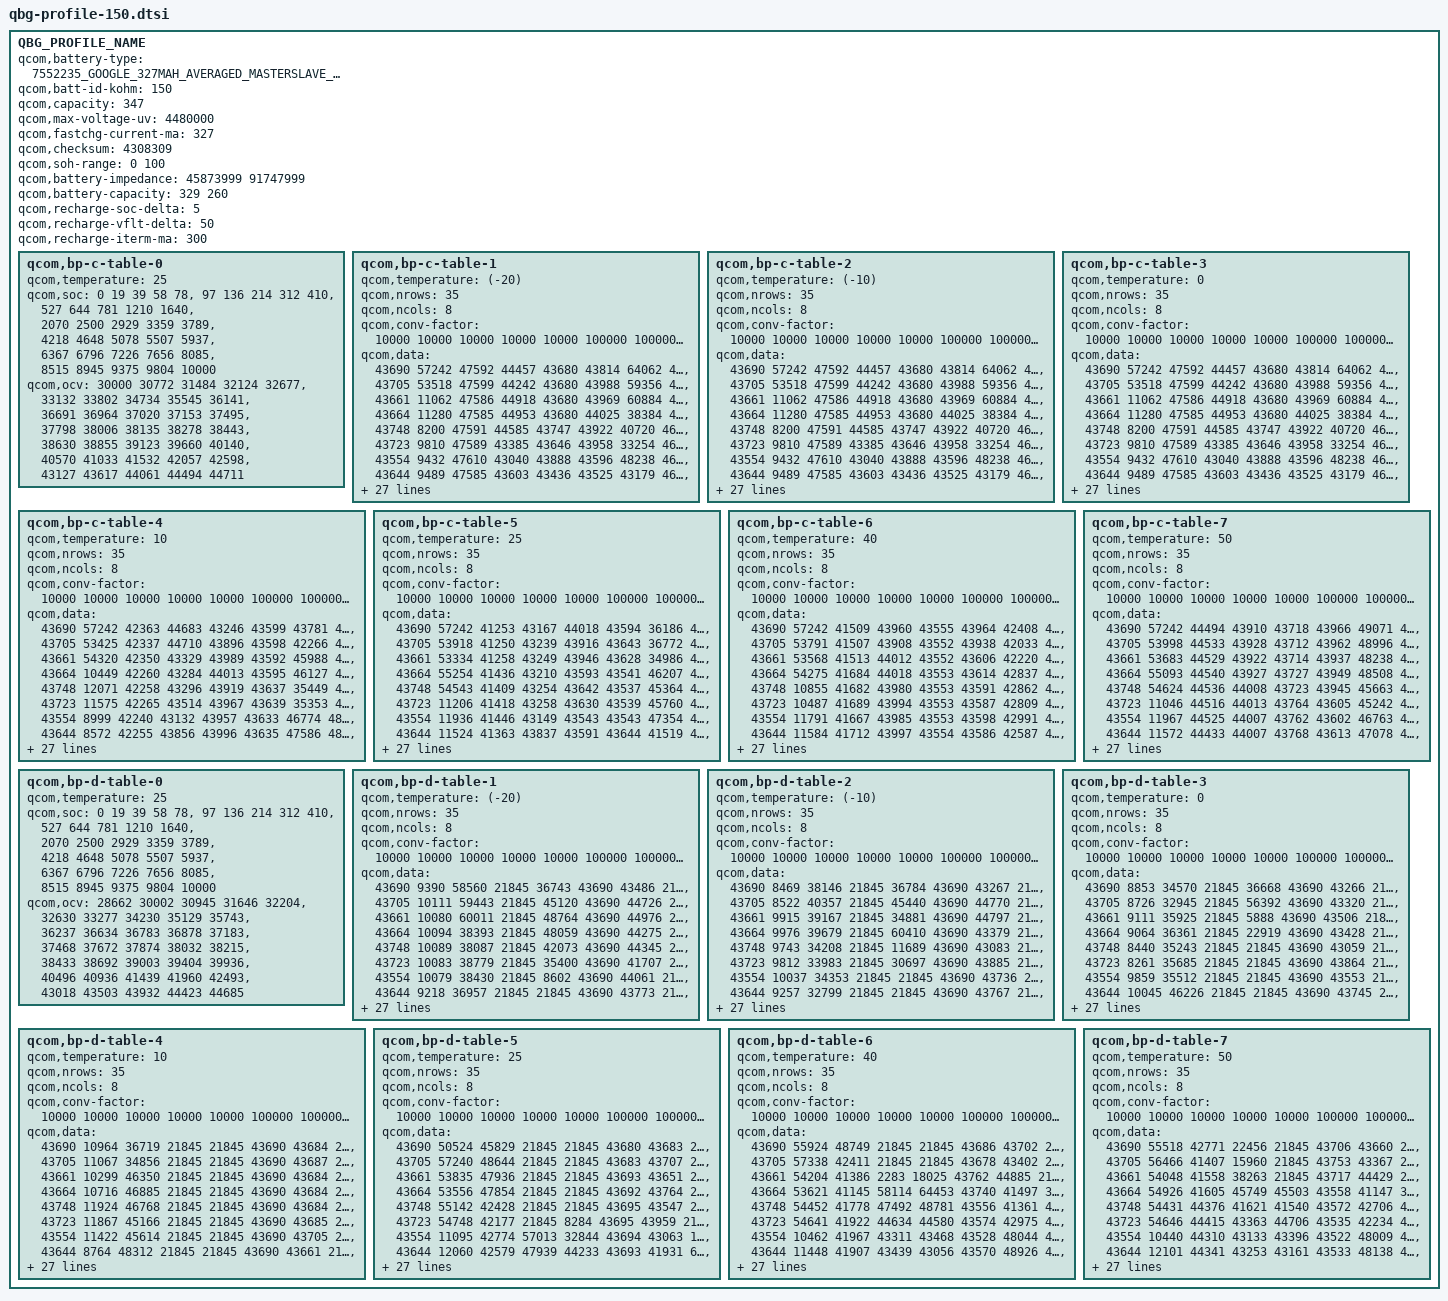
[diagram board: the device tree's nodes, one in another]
/*QBG Profiling Rev. 2.8*/

QBG_PROFILE_NAME {
	qcom,battery-type = "7552235_GOOGLE_327MAH_AVERAGED_MASTERSLAVE_DEC5TH2024";
	qcom,batt-id-kohm = <150>;
	qcom,capacity = <347>;
	qcom,max-voltage-uv = <4480000>;
	qcom,fastchg-current-ma = <327>;
	qcom,checksum = <4308309>; /*@5, 0.005V, 4% */
	qcom,soh-range = <0 100>;
	qcom,battery-impedance = <45873999 91747999>; /*Nominal_Impedance in 10nohm @ SOC 50% 25C* 0:fresh cell, 1: aged cell*/
	qcom,battery-capacity = <329 260>; /*Nominal_Capacity in mAh. 0: fresh cell, 1:aged cell*/
	qcom,recharge-soc-delta =<5>; /*SOC delta (in percent) dropped from EOC SOC to enable recharge*/
	qcom,recharge-vflt-delta =<50>; /*vfloat delta (in mV) dropped from regular vfloat in recharge*/
	qcom,recharge-iterm-ma = <300>; /*termination current (in mA) in recharge*/

	qcom,bp-c-table-0 {
		qcom,temperature = <25>;
		qcom,soc = <    0    19    39    58    78>,
			<   97   136   214   312   410>,
			<  527   644   781  1210  1640>,
			< 2070  2500  2929  3359  3789>,
			< 4218  4648  5078  5507  5937>,
			< 6367  6796  7226  7656  8085>,
			< 8515  8945  9375  9804 10000>;
		qcom,ocv = <30000 30772 31484 32124 32677>,
			<33132 33802 34734 35545 36141>,
			<36691 36964 37020 37153 37495>,
			<37798 38006 38135 38278 38443>,
			<38630 38855 39123 39660 40140>,
			<40570 41033 41532 42057 42598>,
			<43127 43617 44061 44494 44711>;
	};
	qcom,bp-c-table-1 {
		qcom,temperature = <(-20)>;
		qcom,nrows = <35>;
		qcom,ncols = <8>;
		qcom,conv-factor = <10000 10000 10000 10000 10000 100000 100000 10000>;
		qcom,data = <43690 57242 47592 44457 43680 43814 64062 46451>,
			<43705 53518 47599 44242 43680 43988 59356 46342>,
			<43661 11062 47586 44918 43680 43969 60884 46549>,
			<43664 11280 47585 44953 43680 44025 38384 46584>,
			<43748  8200 47591 44585 43747 43922 40720 46477>,
			<43723  9810 47589 43385 43646 43958 33254 46167>,
			<43554  9432 47610 43040 43888 43596 48238 46085>,
			<43644  9489 47585 43603 43436 43525 43179 46233>,
			<43922 15101 47516 43734 43490 43527 43827 46968>,
			<43824 14906 47505 43530 43406 43550 43881 46866>,
			<43173 14956 47515 43632 43402 43542 43847 46927>,
			<43054 14930 47509 43606 43122 43631 43256 46953>,
			<43431 15343 47593 43948 43082 43629 43211 46923>,
			<44560 14386 47451 43973 43345 43551 43857 35504>,
			<44226 14647 48748 41687 43812 43535 45802 36660>,
			<41660 16095 48655 41150 43865 43571 48626 36266>,
			<41838 15938 48842 41369 43248 43571 48468 36126>,
			<41435 16358 48796 41265 43008 43570 48612 33477>,
			<42933 16149 48889 42668 43095 43583 48198 33755>,
			<42087 15609 48691 42711 43496 43576 48579 32804>,
			<47824 15754 48714 42565 43513 43556 45742 33062>,
			<47234 13036 49076 42979 43409 43552 48245 34553>,
			<47484 13160 48939 42793 43393 43561 42013 34745>,
			<48937 12701 48297 42854 43339 43729 41891 33901>,
			<48539 13853 48349 42142 44668 43742 44236 39843>,
			<45685 13555 48225 42185 44893 43719 44571 39404>,
			<45094  2750 48622 42019 44496 43714 43313 40784>,
			<46736  2883 45734 42464 41695 43715 43457 37672>,
			<46914  2428 45670 47694 41579 43743 44705 38863>,
			<46399  3943 45959 42049 42126 43724 43239 59611>,
			<35817  3427 45905 42482 47336 43715 43190 58334>,
			<34907   794 45290 42341 45774 43712 43853 63589>,
			<36405   450 45266 42262 36862 43718 43807 52870>,
			<36070  1977 45070 42978 33964 43725 44030 50412>,
			<36282  1868 45162 41706 33945 43763 43594 50844>;
	};
	qcom,bp-c-table-2 {
		qcom,temperature = <(-10)>;
		qcom,nrows = <35>;
		qcom,ncols = <8>;
		qcom,conv-factor = <10000 10000 10000 10000 10000 100000 100000 10000>;
		qcom,data = <43690 57242 47592 44457 43680 43814 64062 46451>,
			<43705 53518 47599 44242 43680 43988 59356 46342>,
			<43661 11062 47586 44918 43680 43969 60884 46549>,
			<43664 11280 47585 44953 43680 44025 38384 46584>,
			<43748  8200 47591 44585 43747 43922 40720 46477>,
			<43723  9810 47589 43385 43646 43958 33254 46167>,
			<43554  9432 47610 43040 43888 43596 48238 46085>,
			<43644  9489 47585 43603 43436 43525 43179 46233>,
			<43922 15101 47516 43734 43490 43527 43827 46968>,
			<43824 14906 47505 43530 43406 43550 43881 46866>,
			<43173 14956 47515 43632 43402 43542 43847 46927>,
			<43054 14930 47509 43606 43122 43631 43256 46953>,
			<43431 15343 47593 43948 43082 43629 43211 46923>,
			<44560 14386 47451 43973 43345 43551 43857 35504>,
			<44226 14647 48748 41687 43812 43535 45802 36660>,
			<41660 16095 48655 41150 43865 43571 48626 36266>,
			<41838 15938 48842 41369 43248 43571 48468 36126>,
			<41435 16358 48796 41265 43008 43570 48612 33477>,
			<42933 16149 48889 42668 43095 43583 48198 33755>,
			<42087 15609 48691 42711 43496 43576 48579 32804>,
			<47824 15754 48714 42565 43513 43556 45742 33062>,
			<47234 13036 49076 42979 43409 43552 48245 34553>,
			<47484 13160 48939 42793 43393 43561 42013 34745>,
			<48937 12701 48297 42854 43339 43729 41891 33901>,
			<48539 13853 48349 42142 44668 43742 44236 39843>,
			<45685 13555 48225 42185 44893 43719 44571 39404>,
			<45094  2750 48622 42019 44496 43714 43313 40784>,
			<46736  2883 45734 42464 41695 43715 43457 37672>,
			<46914  2428 45670 47694 41579 43743 44705 38863>,
			<46399  3943 45959 42049 42126 43724 43239 59611>,
			<35817  3427 45905 42482 47336 43715 43190 58334>,
			<34907   794 45290 42341 45774 43712 43853 63589>,
			<36405   450 45266 42262 36862 43718 43807 52870>,
			<36070  1977 45070 42978 33964 43725 44030 50412>,
			<36282  1868 45162 41706 33945 43763 43594 50844>;
	};
	qcom,bp-c-table-3 {
		qcom,temperature = <0>;
		qcom,nrows = <35>;
		qcom,ncols = <8>;
		qcom,conv-factor = <10000 10000 10000 10000 10000 100000 100000 10000>;
		qcom,data = <43690 57242 47592 44457 43680 43814 64062 46451>,
			<43705 53518 47599 44242 43680 43988 59356 46342>,
			<43661 11062 47586 44918 43680 43969 60884 46549>,
			<43664 11280 47585 44953 43680 44025 38384 46584>,
			<43748  8200 47591 44585 43747 43922 40720 46477>,
			<43723  9810 47589 43385 43646 43958 33254 46167>,
			<43554  9432 47610 43040 43888 43596 48238 46085>,
			<43644  9489 47585 43603 43436 43525 43179 46233>,
			<43922 15101 47516 43734 43490 43527 43827 46968>,
			<43824 14906 47505 43530 43406 43550 43881 46866>,
			<43173 14956 47515 43632 43402 43542 43847 46927>,
			<43054 14930 47509 43606 43122 43631 43256 46953>,
			<43431 15343 47593 43948 43082 43629 43211 46923>,
			<44560 14386 47451 43973 43345 43551 43857 35504>,
			<44226 14647 48748 41687 43812 43535 45802 36660>,
			<41660 16095 48655 41150 43865 43571 48626 36266>,
			<41838 15938 48842 41369 43248 43571 48468 36126>,
			<41435 16358 48796 41265 43008 43570 48612 33477>,
			<42933 16149 48889 42668 43095 43583 48198 33755>,
			<42087 15609 48691 42711 43496 43576 48579 32804>,
			<47824 15754 48714 42565 43513 43556 45742 33062>,
			<47234 13036 49076 42979 43409 43552 48245 34553>,
			<47484 13160 48939 42793 43393 43561 42013 34745>,
			<48937 12701 48297 42854 43339 43729 41891 33901>,
			<48539 13853 48349 42142 44668 43742 44236 39843>,
			<45685 13555 48225 42185 44893 43719 44571 39404>,
			<45094  2750 48622 42019 44496 43714 43313 40784>,
			<46736  2883 45734 42464 41695 43715 43457 37672>,
			<46914  2428 45670 47694 41579 43743 44705 38863>,
			<46399  3943 45959 42049 42126 43724 43239 59611>,
			<35817  3427 45905 42482 47336 43715 43190 58334>,
			<34907   794 45290 42341 45774 43712 43853 63589>,
			<36405   450 45266 42262 36862 43718 43807 52870>,
			<36070  1977 45070 42978 33964 43725 44030 50412>,
			<36282  1868 45162 41706 33945 43763 43594 50844>;
	};
	qcom,bp-c-table-4 {
		qcom,temperature = <10>;
		qcom,nrows = <35>;
		qcom,ncols = <8>;
		qcom,conv-factor = <10000 10000 10000 10000 10000 100000 100000 10000>;
		qcom,data = <43690 57242 42363 44683 43246 43599 43781 46028>,
			<43705 53425 42337 44710 43896 43598 42266 45960>,
			<43661 54320 42350 43329 43989 43592 45988 45687>,
			<43664 10449 42260 43284 44013 43595 46127 45618>,
			<43748 12071 42258 43296 43919 43637 35449 45820>,
			<43723 11575 42265 43514 43967 43639 35353 45759>,
			<43554  8999 42240 43132 43957 43633 46774 48436>,
			<43644  8572 42255 43856 43996 43635 47586 48195>,
			<43922  9396 42242 43609 43247 43639 43232 48344>,
			<43824  9502 42279 43616 43213 43589 43857 48364>,
			<43173 15062 42454 43717 43067 43938 43835 48962>,
			<43054 14848 42435 43618 43219 43615 43892 48983>,
			<43431 14973 42433 43599 43158 43615 43233 49011>,
			<44560 15125 42296 43384 43589 43642 49101 48586>,
			<44226 14765 42391 44814 43952 43525 45341 45635>,
			<41660 16047 42072 44227 44015 43532 46613 46068>,
			<41838 15900 41989 44154 43971 43529 46028 45861>,
			<41435 16267 42032 44100 43833 43528 48502 45850>,
			<42933 16177 42192 44452 43886 43531 49097 45892>,
			<42087 15489 42193 44541 43867 43572 48356 45260>,
			<47824 15432 42028 44289 43192 43569 45863 45172>,
			<47234 15720 42022 41627 43146 43570 36754 45527>,
			<47484 13307 42036 41710 43845 43582 46484 45520>,
			<48937 12694 42089 41701 43888 43559 42422 45371>,
			<48539 13937 42074 41593 43167 43566 40975 46622>,
			<45685 13356 42386 41972 43034 43734 41608 46217>,
			<45094  2788 42298 41805 43495 43742 44260 46442>,
			<46736  2202 42352 40985 43383 43716 44909 35585>,
			<46914  3717 47773 41356 44641 43713 44670 35090>,
			<46399  3307 47665 41456 44259 43713 43380 36068>,
			<35817   742 48059 41263 41506 43719 43419 33637>,
			<34907   158 48073 41261 42735 43739 43039 33887>,
			<36405   324 47909 41382 48752 43741 43142 37487>,
			<36070  1846 47895 41628 48638 43739 43893 36895>,
			<36282  1229 48122 44669 45780 43715 43947 37711>;
	};
	qcom,bp-c-table-5 {
		qcom,temperature = <25>;
		qcom,nrows = <35>;
		qcom,ncols = <8>;
		qcom,conv-factor = <10000 10000 10000 10000 10000 100000 100000 10000>;
		qcom,data = <43690 57242 41253 43167 44018 43594 36186 47882>,
			<43705 53918 41250 43239 43916 43643 36772 48070>,
			<43661 53334 41258 43249 43946 43628 34986 48019>,
			<43664 55254 41436 43210 43593 43541 46207 48045>,
			<43748 54543 41409 43254 43642 43537 45364 47740>,
			<43723 11206 41418 43258 43630 43539 45760 47628>,
			<43554 11936 41446 43149 43543 43543 47354 47845>,
			<43644 11524 41363 43837 43591 43644 41519 42343>,
			<43922  8307 41351 43611 43819 43944 43108 42450>,
			<43824 10119 41381 43634 43837 43605 43062 42465>,
			<43173  9721 41384 43958 43935 43600 44652 42406>,
			<43054 15054 41049 43615 44027 43639 43474 42055>,
			<43431 14902 41029 43598 43968 43646 43421 42058>,
			<44560 15243 41079 43099 43610 43550 47977 47860>,
			<44226 14557 40962 43370 43907 43533 47279 48051>,
			<41660 14604 41169 44675 43922 43531 48681 48119>,
			<41838 16092 41213 44739 43929 43573 48211 48069>,
			<41435 15965 41111 44764 44011 43530 48613 48068>,
			<42933 16172 41103 44784 43999 43530 47776 48079>,
			<42087 15489 41142 44673 43900 43572 41047 47919>,
			<47824 15436 41123 44696 43180 43569 41226 47875>,
			<47234 15725 41133 44744 43170 43568 42486 47990>,
			<47484 12921 41820 44561 43889 43530 46370 47937>,
			<48937 12358 41819 44578 44027 43575 47384 48027>,
			<48539 13926 41819 44758 44026 43571 41319 48011>,
			<45685 13520 41810 44671 43816 43556 41949 47983>,
			<45094  2787 41147 45009 43898 43563 44405 47180>,
			<46736  2198 41116 44884 43167 43731 44093 48809>,
			<46914  3811 41166 44224 43030 43743 44857 49130>,
			<46399  3276 41008 44032 43308 43742 44546 48143>,
			<35817   733 41074 44106 44555 43740 44683 45770>,
			<34907   203 41392 44102 44035 43732 43475 45476>,
			<36405  1719 41462 44234 41967 43558 43504 46974>,
			<36070  1892 41258 44929 41424 43564 43072 46458>,
			<36282  1037 41031 43289 42842 43742 44017 35391>;
	};
	qcom,bp-c-table-6 {
		qcom,temperature = <40>;
		qcom,nrows = <35>;
		qcom,ncols = <8>;
		qcom,conv-factor = <10000 10000 10000 10000 10000 100000 100000 10000>;
		qcom,data = <43690 57242 41509 43960 43555 43964 42408 40983>,
			<43705 53791 41507 43908 43552 43938 42033 41076>,
			<43661 53568 41513 44012 43552 43606 42220 41042>,
			<43664 54275 41684 44018 43553 43614 42837 41382>,
			<43748 10855 41682 43980 43553 43591 42862 41393>,
			<43723 10487 41689 43994 43553 43587 42809 41356>,
			<43554 11791 41667 43985 43553 43598 42991 41368>,
			<43644 11584 41712 43997 43554 43586 42587 41346>,
			<43922  8265 41703 44028 43567 43600 42739 41025>,
			<43824 10164 41710 44024 43559 43607 41461 41034>,
			<43173  9626 41622 43952 43527 43965 41643 40977>,
			<43054 15074 41630 43916 43717 43939 42478 41173>,
			<43431 15056 41601 43927 43716 43604 48063 41016>,
			<44560 14937 41651 43897 43605 43623 41130 41321>,
			<44226 14485 41642 43159 43910 43538 41152 42745>,
			<41660 14838 44354 43042 43957 43544 47917 42718>,
			<41838 16026 44411 43059 43939 43524 48679 42690>,
			<41435 15993 44309 43067 43951 43524 47775 42723>,
			<42933 16325 44294 43068 43917 43544 42881 42696>,
			<42087 15497 44342 43188 43848 43551 44927 42535>,
			<47824 15429 44347 43184 43187 43524 44179 42602>,
			<47234 15735 44322 43256 43196 43522 41587 42566>,
			<47484 12886 44329 43036 43899 43522 48088 42920>,
			<48937 12709 44503 43060 43910 43523 42935 42733>,
			<48539 13943 44499 43206 44009 43522 44351 42654>,
			<45685 13375 44496 43229 43994 43531 44839 42695>,
			<45094  2754 44501 43017 43827 43568 44658 42610>,
			<46736  2292 44332 43402 43897 43558 44555 42765>,
			<46914  3783 44344 43280 43149 43560 44752 42008>,
			<46399  3104 44294 44718 43018 43563 44681 42297>,
			<35817   572 44386 44768 43415 43564 44713 47674>,
			<34907   223 44355 44554 44728 43580 44793 47936>,
			<36405  1668 41636 43289 44771 43528 44671 48023>,
			<36070  1870 41631 43410 44035 43573 43484 47558>,
			<36282  1130 44540 43871 42645 43568 43973 48192>;
	};
	qcom,bp-c-table-7 {
		qcom,temperature = <50>;
		qcom,nrows = <35>;
		qcom,ncols = <8>;
		qcom,conv-factor = <10000 10000 10000 10000 10000 100000 100000 10000>;
		qcom,data = <43690 57242 44494 43910 43718 43966 49071 41880>,
			<43705 53998 44533 43928 43712 43962 48996 41965>,
			<43661 53683 44529 43922 43714 43937 48238 41971>,
			<43664 55093 44540 43927 43727 43949 48508 41923>,
			<43748 54624 44536 44008 43723 43945 45663 41951>,
			<43723 11046 44516 44013 43764 43605 45242 41941>,
			<43554 11967 44525 44007 43762 43602 46763 41766>,
			<43644 11572 44433 44007 43768 43613 47078 41762>,
			<43922  8296 44443 44002 43774 43601 45499 41949>,
			<43824  9812 44417 43606 43553 43966 41088 41976>,
			<43173  9301 44431 43588 43579 43905 41244 41873>,
			<43054 15030 44469 43643 43716 43911 41335 41561>,
			<43431 15073 44464 43584 43727 43915 47665 41898>,
			<44560 14946 44452 43982 43606 43585 41692 41090>,
			<44226 14525 44116 43827 43958 43633 41474 41174>,
			<41660 14725 44122 43794 43915 43647 42723 41017>,
			<41838 16035 44105 43792 43941 43642 42876 41171>,
			<41435 15894 44156 43878 43597 43623 42147 41204>,
			<42933 16335 44131 43889 43605 43642 42703 41000>,
			<42087 15499 44055 43998 43804 43639 44954 40983>,
			<47824 15453 44060 44004 43175 43643 44636 41028>,
			<47234 15685 44037 43815 43857 43629 44392 41403>,
			<47484 13237 44032 43855 43776 43629 42424 41405>,
			<48937 12673 44044 43850 43946 43629 42504 41152>,
			<48539 13918 44046 43837 43917 43619 44271 41190>,
			<45685 13316 44041 43836 43983 43624 44687 40994>,
			<45094  2601 44047 43891 43999 43544 44794 41053>,
			<46736  2262 44032 43136 43833 43535 44778 41428>,
			<46914  3621 44058 43042 43840 43570 43391 42732>,
			<46399  3087 44051 43429 43156 43576 44713 42884>,
			<35817   514 44141 43507 43057 43576 44791 42817>,
			<34907    47 44146 43470 43481 43568 44705 42085>,
			<36405  1692 44100 43032 43421 43525 45012 42877>,
			<36070  1856 44116 43070 44627 43550 44708 42279>,
			<36282  1127 44241 43197 41546 43539 43897 47261>;
	};
	qcom,bp-d-table-0 {
		qcom,temperature = <25>;
		qcom,soc = <    0    19    39    58    78>,
			<   97   136   214   312   410>,
			<  527   644   781  1210  1640>,
			< 2070  2500  2929  3359  3789>,
			< 4218  4648  5078  5507  5937>,
			< 6367  6796  7226  7656  8085>,
			< 8515  8945  9375  9804 10000>;
		qcom,ocv = <28662 30002 30945 31646 32204>,
			<32630 33277 34230 35129 35743>,
			<36237 36634 36783 36878 37183>,
			<37468 37672 37874 38032 38215>,
			<38433 38692 39003 39404 39936>,
			<40496 40936 41439 41960 42493>,
			<43018 43503 43932 44423 44685>;
	};
	qcom,bp-d-table-1 {
		qcom,temperature = <(-20)>;
		qcom,nrows = <35>;
		qcom,ncols = <8>;
		qcom,conv-factor = <10000 10000 10000 10000 10000 100000 100000 10000>;
		qcom,data = <43690  9390 58560 21845 36743 43690 43486 21845>,
			<43705 10111 59443 21845 45120 43690 44726 21845>,
			<43661 10080 60011 21845 48764 43690 44976 21845>,
			<43664 10094 38393 21845 48059 43690 44275 21845>,
			<43748 10089 38087 21845 42073 43690 44345 21845>,
			<43723 10083 38779 21845 35400 43690 41707 21845>,
			<43554 10079 38430 21845  8602 43690 44061 21845>,
			<43644  9218 36957 21845 21845 43690 43773 21845>,
			<43922  9303 36887 21845  6087 43690 43731 21845>,
			<43824  9607 37022 21845 55622 43690 43579 21845>,
			<43173  9669 40149 21845 59179 43690 43523 21845>,
			<43054  9495 40861 21845 39998 43690 43585 21845>,
			<43431 15034 39288 21845 33416 43690 44009 21845>,
			<44560 14949 39456 23215 36810 43691 43898 21845>,
			<44226 15317 34023 12936 46136 43691 43256 21845>,
			<41660 14516 33147 50890 45724 43688 43111 21845>,
			<41838 14362 33557 58835 47229 43688 43397 24414>,
			<41435 14829 33477 38142 42486 43689 43322 31638>,
			<42933 14666 36132 39778 42599 43689 43389  8129>,
			<42087 15906 36086 33726 41396 43694 44681  2986>,
			<47824 16278 36753 34893 41854 43695 44760 15328>,
			<47234 15535 36581 46120 41693 43692 44983 11984>,
			<47484 15446 35111 45370 44438 43693 44140 53450>,
			<48937 13028 35216 45238 44060 43682 41776 56982>,
			<48539 13138 34901 46003 44350 43682 41471 56110>,
			<45685 12663 34878 45767 41664 43683 42932 55997>,
			<45094 13486 35014 45615 41739 43680 42118 55918>,
			<46736  2749 35064 45619 41030 43681 42934 56081>,
			<46914  2206 35047 45775 41254 43703 42709 55296>,
			<46399  3626 35016 45717 41342 43669 42123 55621>,
			<35817  3126 35669 45659 42702 43670 42603 56950>,
			<34907   520 35054 45974 42698 43677 41155 57262>,
			<36405    14 35652 45930 41192 43652 41498 55806>,
			<36070  1943 35752 45266 44249 43659 44348 55950>,
			<36282  1050 35539 45114 44826 43696 44482 50648>;
	};
	qcom,bp-d-table-2 {
		qcom,temperature = <(-10)>;
		qcom,nrows = <35>;
		qcom,ncols = <8>;
		qcom,conv-factor = <10000 10000 10000 10000 10000 100000 100000 10000>;
		qcom,data = <43690  8469 38146 21845 36784 43690 43267 21845>,
			<43705  8522 40357 21845 45440 43690 44770 21845>,
			<43661  9915 39167 21845 34881 43690 44797 21845>,
			<43664  9976 39679 21845 60410 43690 43379 21845>,
			<43748  9743 34208 21845 11689 43690 43083 21845>,
			<43723  9812 33983 21845 30697 43690 43885 21845>,
			<43554 10037 34353 21845 21845 43690 43736 21845>,
			<43644  9257 32799 21845 21845 43690 43767 21845>,
			<43922  9302 33758 21845 49551 43690 43568 21845>,
			<43824  9715 33423 21845 40905 43690 43585 21845>,
			<43173  9500 36045 21845 46138 43690 44019 21845>,
			<43054 15021 36822 30323 47402 43690 43844 21845>,
			<43431 15093 35202 56473 42956 43691 43106 21845>,
			<44560 15234 35468 40682 41079 43688 43340  6002>,
			<44226 15124 46856 34935 41908 43689 44581 10033>,
			<41660 14564 46796 45950 44447 43695 44948 55427>,
			<41838 14455 45508 48652 44893 43693 44814 51373>,
			<41435 14789 45536 47935 44959 43680 44172 62284>,
			<42933 16039 45510 42301 44644 43687 44078 65076>,
			<42087 15969 45509 42024 44745 43707 44367 64393>,
			<47824 16250 45532 42870 44673 43650 42512 58625>,
			<47234 15799 45353 42895 44584 43745 47741 58855>,
			<47484 12833 45518 42531 44986 43731 48091 58830>,
			<48937 13141 45507 42517 44803 43735 41989 58861>,
			<48539 12561 45331 42975 44267 43560 41998 58751>,
			<45685 14088 45370 42118 44464 43563 42949 64037>,
			<45094 13578 45559 42392 44350 43734 42514 64469>,
			<46736  2845 45460 47828 44381 43743 42506 63595>,
			<46914  2416 45444 47925 41686 43713 42720 63836>,
			<46399  3904 45459 47317 41566 43721 41457 65419>,
			<35817  3440 45498 47592 41952 43766 41100 64666>,
			<34907   819 45152 47487 41889 43775 41572 64624>,
			<36405   490 45144 47444 44543 43745 41508 64654>,
			<36070  2014 45349 47378 44768 43754 41577 65202>,
			<36282  1055 45395 47602 43468 43664 41908 63918>;
	};
	qcom,bp-d-table-3 {
		qcom,temperature = <0>;
		qcom,nrows = <35>;
		qcom,ncols = <8>;
		qcom,conv-factor = <10000 10000 10000 10000 10000 100000 100000 10000>;
		qcom,data = <43690  8853 34570 21845 36668 43690 43266 21845>,
			<43705  8726 32945 21845 56392 43690 43320 21845>,
			<43661  9111 35925 21845  5888 43690 43506 21845>,
			<43664  9064 36361 21845 22919 43690 43428 21845>,
			<43748  8440 35243 21845 21845 43690 43059 21845>,
			<43723  8261 35685 21845 21845 43690 43864 21845>,
			<43554  9859 35512 21845 21845 43690 43553 21845>,
			<43644 10045 46226 21845 21845 43690 43745 21845>,
			<43922  9262 46717 21845 64215 43690 43532 21845>,
			<43824  9639 45408 21845 46291 43690 43908 21845>,
			<43173  9694 45096 27370 42890 43690 43136 21845>,
			<43054  9492 45858 63688 44355 43691 43428 23464>,
			<43431 15008 45684 36430 44214 43688 43323  2301>,
			<44560 14914 48249 42565 43323 43695 44064 62103>,
			<44226 15134 48924 42427 43501 43682 41022 64199>,
			<41660 14559 49100 42558 43460 43706 42748 60697>,
			<41838 14721 49098 41089 43441 43772 47160 59579>,
			<41435 14620 48955 41898 43131 43742 47875 38702>,
			<42933 16123 48941 41573 43104 43728 47661 37076>,
			<42087 16284 49109 41572 43101 43562 47196 37810>,
			<47824 15597 48943 41596 43319 43561 47330 37586>,
			<47234 15858 49009 41577 44723 43566 42942 40256>,
			<47484 12810 48968 41917 44758 43554 41461 40312>,
			<48937 12426 48915 41836 44644 43554 41354 37543>,
			<48539 12659 48950 41017 45054 43561 41004 37379>,
			<45685 14176 48902 41267 44875 43734 41137 37642>,
			<45094 13643 48922 42592 44262 43742 41145 36970>,
			<46736  2901 48955 42855 44054 43715 41748 37241>,
			<46914  3775 48932 42023 44427 43722 41534 38527>,
			<46399  3215 49141 42473 44436 43761 41623 38783>,
			<35817   689 49100 42313 44437 43773 41632 37892>,
			<34907   841 49041 47865 44109 43769 41661 38286>,
			<36405   464 49049 47803 44806 43751 41685 38110>,
			<36070  1836 49148 42429 43324 43753 41876 38454>,
			<36282  1050 49118 42203 43112 43668 41951 37216>;
	};
	qcom,bp-d-table-4 {
		qcom,temperature = <10>;
		qcom,nrows = <35>;
		qcom,ncols = <8>;
		qcom,conv-factor = <10000 10000 10000 10000 10000 100000 100000 10000>;
		qcom,data = <43690 10964 36719 21845 21845 43690 43684 21845>,
			<43705 11067 34856 21845 21845 43690 43687 21845>,
			<43661 10299 46350 21845 21845 43690 43684 21845>,
			<43664 10716 46885 21845 21845 43690 43684 21845>,
			<43748 11924 46768 21845 21845 43690 43684 21845>,
			<43723 11867 45166 21845 21845 43690 43685 21845>,
			<43554 11422 45614 21845 21845 43690 43705 21845>,
			<43644  8764 48312 21845 21845 43690 43661 21845>,
			<43922  8600 48888 21845  3391 43690 43557 21845>,
			<43824 10216 47563 21845 46422 43690 43827 21845>,
			<43173  9324 47158 53024 41152 43691 43513 21845>,
			<43054  9713 47253 36490 45050 43691 44968 12821>,
			<43431  9473 47908 42848 43509 43694 44240 62796>,
			<44560 14995 47916 44223 43853 43650 41694 40843>,
			<44226 15136 48040 44139 43221 43761 42828 39025>,
			<41660 14374 47631 44154 43428 43731 42250 34000>,
			<41838 14722 47635 44071 43429 43560 42175 32920>,
			<41435 14598 47636 44235 43009 43554 42872 36273>,
			<42933 16067 47728 44077 43056 43559 47194 36630>,
			<42087 16363 47627 44231 43095 43556 47653 36768>,
			<47824 15496 47647 44256 43501 43556 41312 36602>,
			<47234 15749 47726 44241 43509 43579 41110 35142>,
			<47484 13022 47717 44121 43479 43557 41108 36514>,
			<48937 13145 47722 44331 43292 43552 41193 36551>,
			<48539 12651 47623 41628 44721 43565 40976 36757>,
			<45685 14154 47630 41953 44554 43567 42496 35858>,
			<45094  2744 47627 41089 44929 43733 42999 33414>,
			<46736  2213 47636 41165 44855 43739 41879 33365>,
			<46914  3766 47836 41081 44817 43718 44355 33656>,
			<46399  3201 47830 41456 44853 43725 44347 32821>,
			<35817   647 47811 41321 45022 43721 44384 33252>,
			<34907   171 47817 41286 44959 43722 41606 33144>,
			<36405   308 47817 41240 44590 43760 41597 33031>,
			<36070  1851 47822 41388 43514 43768 41831 32866>,
			<36282  1036 47823 41066 43108 43748 41192 32956>;
	};
	qcom,bp-d-table-5 {
		qcom,temperature = <25>;
		qcom,nrows = <35>;
		qcom,ncols = <8>;
		qcom,conv-factor = <10000 10000 10000 10000 10000 100000 100000 10000>;
		qcom,data = <43690 50524 45829 21845 21845 43680 43683 21845>,
			<43705 57240 48644 21845 21845 43683 43707 21845>,
			<43661 53835 47936 21845 21845 43693 43651 21845>,
			<43664 53556 47854 21845 21845 43692 43764 21845>,
			<43748 55142 42428 21845 21845 43695 43547 21845>,
			<43723 54748 42177 21845  8284 43695 43959 21845>,
			<43554 11095 42774 57013 32844 43694 43063 19130>,
			<43644 12060 42579 47939 44233 43693 41931 65524>,
			<43922  9107 42558 44032 43490 43675 48748 39424>,
			<43824  8501 42548 45054 43075 43771 45902 35920>,
			<43173 10023 42529 44588 43183 43723 47902 35541>,
			<43054  9648 42718 44692 43194 43741 41056 46977>,
			<43431  9477 42738 44673 43873 43741 41183 45499>,
			<44560 15012 42626 43451 43944 43555 42552 49010>,
			<44226 15253 42686 43513 43821 43557 41274 48952>,
			<41660 14582 41237 43271 43153 43581 41176 48950>,
			<41838 14722 41256 43287 43042 43531 41393 49072>,
			<41435 14680 41250 43344 43038 43545 47784 49066>,
			<42933 15930 41465 43276 43086 43521 41382 48832>,
			<42087 16365 41455 43268 43028 43524 41786 47444>,
			<47824 15499 41369 43372 43220 43526 41887 47411>,
			<47234 15758 41398 43331 43240 43522 41728 47611>,
			<47484 13041 41383 44718 43159 43528 41122 47587>,
			<48937 13126 41391 44770 43230 43531 42671 47370>,
			<48539 13994 41047 44614 43409 43523 42316 49086>,
			<45685 13466 41037 44930 44691 43529 42384 48362>,
			<45094 13634 41025 44660 44780 43556 41640 48314>,
			<46736  2933 41040 44988 43344 43577 44458 48279>,
			<46914  2370 41391 45031 43326 43577 44081 48275>,
			<46399  3927 41403 44810 43455 43579 44434 48353>,
			<35817   672 41369 44916 43032 43578 41479 48341>,
			<34907   837 41362 44819 43033 43558 41965 48142>,
			<36405   310 41451 45004 43012 43552 41949 48191>,
			<36070  1837 41471 44632 43064 43565 41934 48334>,
			<36282  1063 41462 44655 43048 43564 41546 48382>;
	};
	qcom,bp-d-table-6 {
		qcom,temperature = <40>;
		qcom,nrows = <35>;
		qcom,ncols = <8>;
		qcom,conv-factor = <10000 10000 10000 10000 10000 100000 100000 10000>;
		qcom,data = <43690 55924 48749 21845 21845 43686 43702 21845>,
			<43705 57338 42411 21845 21845 43678 43402 21845>,
			<43661 54204 41386  2283 18025 43762 44885 21845>,
			<43664 53621 41145 58114 64453 43740 41497   396>,
			<43748 54452 41778 47492 48781 43556 41361 40700>,
			<43723 54641 41922 44634 44580 43574 42975 49120>,
			<43554 10462 41967 43311 43468 43528 48044 47269>,
			<43644 11448 41907 43439 43056 43570 48926 47871>,
			<43922  9191 41540 43104 43226 43531 45469 42292>,
			<43824  8510 41597 43031 43016 43532 46494 42278>,
			<43173 10189 41576 43022 43803 43521 46496 42234>,
			<43054  9281 41498 43011 43957 43523 48073 42755>,
			<43431  9571 41484 43097 43930 43520 41270 42154>,
			<44560 15032 41685 43875 43534 43543 42344 41283>,
			<44226 15284 41717 43173 43960 43618 42751 42693>,
			<41660 14494 41630 43235 43822 43627 41154 42587>,
			<41838 14723 41652 43257 43193 43625 41040 42957>,
			<41435 16033 41633 43215 43065 43596 41830 42829>,
			<42933 15897 44371 43022 43158 43946 41147 42774>,
			<42087 16350 44364 43112 43856 43584 41452 42795>,
			<47824 15611 44413 43033 43883 43644 41410 42881>,
			<47234 15846 44390 43042 43820 43631 41024 42515>,
			<47484 13009 44392 43222 43988 43539 41369 42506>,
			<48937 12433 44307 43034 43179 43624 42477 42999>,
			<48539 14067 44319 43084 43494 43629 47676 42081>,
			<45685 13498 44319 43068 43313 43521 44527 42099>,
			<45094 13645 44305 43075 43407 43539 44144 42085>,
			<46736  2936 44392 43477 43163 43640 41512 42016>,
			<46914  2418 44411 43281 43824 43624 41841 42221>,
			<46399  3931 44360 43286 44010 43527 42510 42145>,
			<35817  3413 44370 43479 43927 43572 42517 42877>,
			<34907   846 41661 43394 44030 43568 41341 42774>,
			<36405   310 41603 43123 43817 43530 41379 42755>,
			<36070  2013 41602 43064 43885 43547 40982 42800>,
			<36282  1231 41654 43231 43855 43549 41085 42813>;
	};
	qcom,bp-d-table-7 {
		qcom,temperature = <50>;
		qcom,nrows = <35>;
		qcom,ncols = <8>;
		qcom,conv-factor = <10000 10000 10000 10000 10000 100000 100000 10000>;
		qcom,data = <43690 55518 42771 22456 21845 43706 43660 21845>,
			<43705 56466 41407 15960 21845 43753 43367 21845>,
			<43661 54048 41558 38263 21845 43717 44429 21845>,
			<43664 54926 41605 45749 45503 43558 41147 38292>,
			<43748 54431 44376 41621 41540 43572 42706 45448>,
			<43723 54646 44415 43363 44706 43535 42234 48057>,
			<43554 10440 44310 43133 43396 43522 48009 42079>,
			<43644 12101 44341 43253 43161 43533 48138 42909>,
			<43922  9100 44335 43152 43143 43544 46637 42564>,
			<43824  8640 44504 43149 43255 43549 46188 42563>,
			<43173 10221 44532 43197 43779 43540 35533 41302>,
			<43054  9321 44539 43140 43614 43539 48445 41462>,
			<43431  9484 44515 43219 43591 43550 42860 41267>,
			<44560  9563 44443 44007 43552 43636 47925 41839>,
			<44226 14935 44471 43789 43638 43584 42394 41202>,
			<41660 14526 44462 43851 43930 43585 42998 41087>,
			<41838 14762 44126 43800 43779 43614 41181 41390>,
			<41435 14676 44102 43196 43181 43920 41125 41318>,
			<42933 15992 44107 43263 43197 43917 41241 42683>,
			<42087 16191 44157 43152 43869 43942 41196 41342>,
			<47824 15553 44133 43155 43821 43947 41404 41460>,
			<47234 15816 44130 43173 43921 43597 41040 41083>,
			<47484 12856 44142 43849 43920 43635 41440 40987>,
			<48937 12512 44053 43869 43890 43647 42627 41469>,
			<48539 14026 44049 43184 43093 43643 41041 42497>,
			<45685 13450 44048 43196 43444 43640 44092 42599>,
			<45094 13633 44052 43229 43227 43634 44095 42557>,
			<46736  2943 44143 43519 43931 43589 42936 42720>,
			<46914  2421 44154 43449 43958 43539 41409 42665>,
			<46399  3933 44151 43122 43600 43534 42589 41245>,
			<35817   683 44108 43047 43589 43532 42814 41423>,
			<34907   841 44127 43158 43601 43547 42608 41358>,
			<36405   307 44463 43180 43919 43624 41335 41393>,
			<36070  2008 44477 43844 43974 43635 41033 41465>,
			<36282  1226 44426 43871 43809 43598 40971 41262>;
	};
};
